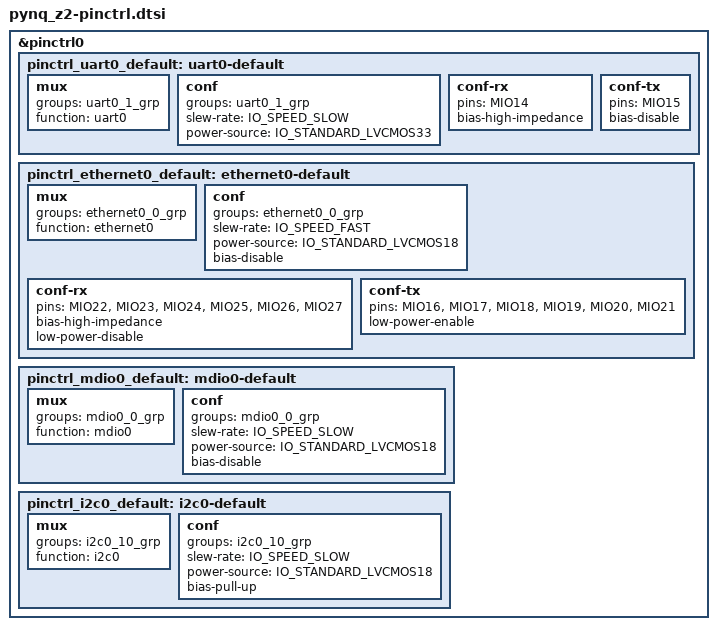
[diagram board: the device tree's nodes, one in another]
/*
 * Copyright (c) 2026 Radu Pirea
 *
 * SPDX-License-Identifier: Apache-2.0
 */

#include <zephyr/dt-bindings/pinctrl/pinctrl-zynq.h>

&pinctrl0 {
	pinctrl_uart0_default: uart0-default {
		mux {
			groups = "uart0_1_grp";
			function = "uart0";
		};

		conf {
			groups = "uart0_1_grp";
			slew-rate = <IO_SPEED_SLOW>;
			power-source = <IO_STANDARD_LVCMOS33>;
		};

		conf-rx {
			pins = "MIO14";
			bias-high-impedance;
		};

		conf-tx {
			pins = "MIO15";
			bias-disable;
		};
	};

	pinctrl_ethernet0_default: ethernet0-default {
		mux {
			groups = "ethernet0_0_grp";
			function = "ethernet0";
		};

		conf {
			groups = "ethernet0_0_grp";
			slew-rate = <IO_SPEED_FAST>;
			power-source = <IO_STANDARD_LVCMOS18>;
			bias-disable;
		};

		conf-rx {
			pins = "MIO22", "MIO23", "MIO24", "MIO25", "MIO26", "MIO27";
			bias-high-impedance;
			low-power-disable;
		};

		conf-tx {
			pins = "MIO16", "MIO17", "MIO18", "MIO19", "MIO20", "MIO21";
			low-power-enable;
		};
	};

	pinctrl_mdio0_default: mdio0-default {
		mux {
			groups = "mdio0_0_grp";
			function = "mdio0";
		};

		conf {
			groups = "mdio0_0_grp";
			slew-rate = <IO_SPEED_SLOW>;
			power-source = <IO_STANDARD_LVCMOS18>;
			bias-disable;
		};
	};

	pinctrl_i2c0_default: i2c0-default {
		mux {
			groups = "i2c0_10_grp";
			function = "i2c0";
		};

		conf {
			groups = "i2c0_10_grp";
			slew-rate = <IO_SPEED_SLOW>;
			power-source = <IO_STANDARD_LVCMOS18>;
			bias-pull-up;
		};
	};
};
